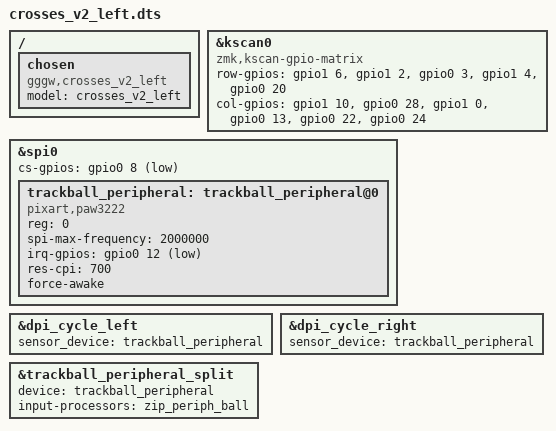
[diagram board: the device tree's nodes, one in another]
/*
 * Copyright (c) 2026 Vincent Franco
 * SPDX-License-Identifier: MIT
 */

#include "crosses_v2.dts"
#include <zephyr/dt-bindings/input/input-event-codes.h>
#include <input/processors.dtsi>

/ {
  chosen {
    model = "crosses_v2_left";
    compatible = "gggw,crosses_v2_left";
  };
};

&kscan0 {
  compatible = "zmk,kscan-gpio-matrix";

  row-gpios
    = <&gpio1 6 (GPIO_ACTIVE_HIGH | GPIO_PULL_DOWN)>
    , <&gpio1 2 (GPIO_ACTIVE_HIGH | GPIO_PULL_DOWN)>
    , <&gpio0 3 (GPIO_ACTIVE_HIGH | GPIO_PULL_DOWN)>
    , <&gpio1 4 (GPIO_ACTIVE_HIGH | GPIO_PULL_DOWN)>
    , <&gpio0 20 (GPIO_ACTIVE_HIGH | GPIO_PULL_DOWN)>
    ;

  col-gpios
    = <&gpio1 10 GPIO_ACTIVE_HIGH>
    , <&gpio0 28 GPIO_ACTIVE_HIGH>
    , <&gpio1 0 GPIO_ACTIVE_HIGH>
    , <&gpio0 13 GPIO_ACTIVE_HIGH>
    , <&gpio0 22 GPIO_ACTIVE_HIGH>
    , <&gpio0 24 GPIO_ACTIVE_HIGH>
    ;
};

&spi0 {
    cs-gpios = <&gpio0 8 GPIO_ACTIVE_LOW>;

    trackball_peripheral: trackball_peripheral@0 {
        status = "okay";
        compatible = "pixart,paw3222";
        reg = <0>;
        spi-max-frequency = <2000000>;
        irq-gpios = <&gpio0 12 GPIO_ACTIVE_LOW>;
        res-cpi = <700>;
        force-awake;
    };
};

&dpi_cycle_left {
    sensor_device = <&trackball_peripheral>;
};

// Never invoked on this half (EVENT_SOURCE locality runs it on the right
// half); points at the local sensor only to satisfy the required phandle.
&dpi_cycle_right {
    sensor_device = <&trackball_peripheral>;
};

// Overrides for the input-split child node
&trackball_peripheral_split {
    device = <&trackball_peripheral>;
    input-processors = <&zip_periph_ball>;
};
